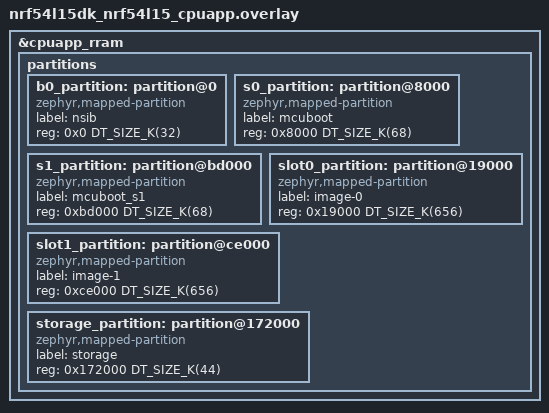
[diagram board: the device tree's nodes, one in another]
/*
 * Copyright (c) 2026 Nordic Semiconductor ASA
 *
 * SPDX-License-Identifier: LicenseRef-Nordic-5-Clause
 */

/delete-node/ &boot_partition;
/delete-node/ &slot0_partition;
/delete-node/ &slot1_partition;
/delete-node/ &storage_partition;

&cpuapp_rram {
	partitions {
		b0_partition: partition@0 {
			compatible = "zephyr,mapped-partition";
			label = "nsib";
			reg = <0x0 DT_SIZE_K(32)>;
		};

		s0_partition: partition@8000 {
			compatible = "zephyr,mapped-partition";
			label = "mcuboot";
			reg = <0x8000 DT_SIZE_K(68)>;
		};

		s1_partition: partition@bd000 {
			compatible = "zephyr,mapped-partition";
			label = "mcuboot_s1";
			reg = <0xbd000 DT_SIZE_K(68)>;
		};

		slot0_partition: partition@19000 {
			compatible = "zephyr,mapped-partition";
			label = "image-0";
			reg = <0x19000 DT_SIZE_K(656)>;
		};

		slot1_partition: partition@ce000 {
			compatible = "zephyr,mapped-partition";
			label = "image-1";
			reg = <0xce000 DT_SIZE_K(656)>;
		};

		storage_partition: partition@172000 {
			compatible = "zephyr,mapped-partition";
			label = "storage";
			reg = <0x172000 DT_SIZE_K(44)>;
		};
	};
};
